# EFM32GG990F1024 register map
File version: 1.6
Registers are 32-bit, read-write, reset 0x0 unless marked. A register's access mark holds for its fields unless they carry their own. Offsets are from the block's base; [hi:lo] are bit positions; {n}, {i} and the like mark numbered series.

## RMU
Base 0x400CA000
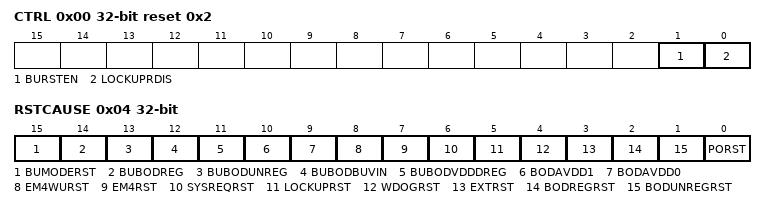
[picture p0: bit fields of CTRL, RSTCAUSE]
0x00 CTRL reset 0x2 — Control Register
  [1] BURSTEN — Backup domain reset enable.
  [0] LOCKUPRDIS — Lockup Reset Disable
0x04 RSTCAUSE ro — Reset Cause Register
  [15] BUMODERST — Backup mode reset
  [14] BUBODREG — Backup Brown Out Detector Regulated Domain
  [13] BUBODUNREG — Backup Brown Out Detector Unregulated Domain
  [12] BUBODBUVIN — Backup Brown Out Detector, BU_VIN
  [11] BUBODVDDDREG — Backup Brown Out Detector, VDD_DREG
  [10] BODAVDD1 — AVDD1 Bod Reset.
  [9] BODAVDD0 — AVDD0 Bod Reset.
  [8] EM4WURST — EM4 Wake-up Reset
  [7] EM4RST — EM4 Reset
  [6] SYSREQRST — System Request Reset
  [5] LOCKUPRST — LOCKUP Reset
  [4] WDOGRST — Watchdog Reset
  [3] EXTRST — External Pin Reset
  [2] BODREGRST — Brown Out Detector Regulated Domain Reset
  [1] BODUNREGRST — Brown Out Detector Unregulated Domain Reset
  [0] PORST — Power On Reset
0x08 CMD wo — Command Register
  [0] RCCLR — Reset Cause Clear

## AES
Base 0x400E0000
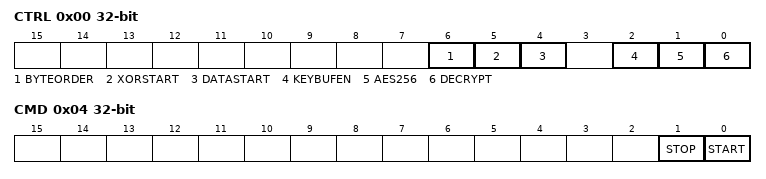
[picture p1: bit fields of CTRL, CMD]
0x00 CTRL — Control Register
  [6] BYTEORDER — Configure byte order in data and key registers
  [5] XORSTART — AES_XORDATA Write Start
  [4] DATASTART — AES_DATA Write Start
  [2] KEYBUFEN — Key Buffer Enable
  [1] AES256 — AES-256 Mode
  [0] DECRYPT — Decryption/Encryption Mode
0x04 CMD wo — Command Register
  [1] STOP — Encryption/Decryption Stop
  [0] START — Encryption/Decryption Start
0x08 STATUS ro
  [0] RUNNING — AES Running
0x0C IEN — Interrupt Enable Register
  [0] DONE — Encryption/Decryption Done Interrupt Enable
0x10 IF ro — Interrupt Flag Register
  [0] DONE — Encryption/Decryption Done Interrupt Flag
0x14 IFS wo — Interrupt Flag Set Register
  [0] DONE — Encryption/Decryption Done Interrupt Flag Set
0x18 IFC wo — Interrupt Flag Clear Register
  [0] DONE — Encryption/Decryption Done Interrupt Flag Clear
0x1C DATA read-has-side-effects
  [31:0] DATA — Data Access
0x20 XORDATA
  [31:0] XORDATA — XOR Data Access
0x30 KEYLA read-has-side-effects — KEY Low Register
  [31:0] KEYLA — Key Low Access A
0x34 KEYLB read-has-side-effects — KEY Low Register
  [31:0] KEYLB — Key Low Access B
0x38 KEYLC read-has-side-effects — KEY Low Register
  [31:0] KEYLC — Key Low Access C
0x3C KEYLD read-has-side-effects — KEY Low Register
  [31:0] KEYLD — Key Low Access D
0x40 KEYHA read-has-side-effects — KEY High Register
  [31:0] KEYHA — Key High Access A
0x44 KEYHB read-has-side-effects — KEY High Register
  [31:0] KEYHB — Key High Access B
0x48 KEYHC read-has-side-effects — KEY High Register
  [31:0] KEYHC — Key High Access C
0x4C KEYHD read-has-side-effects — KEY High Register
  [31:0] KEYHD — Key High Access D

## PRS
Base 0x400CC000
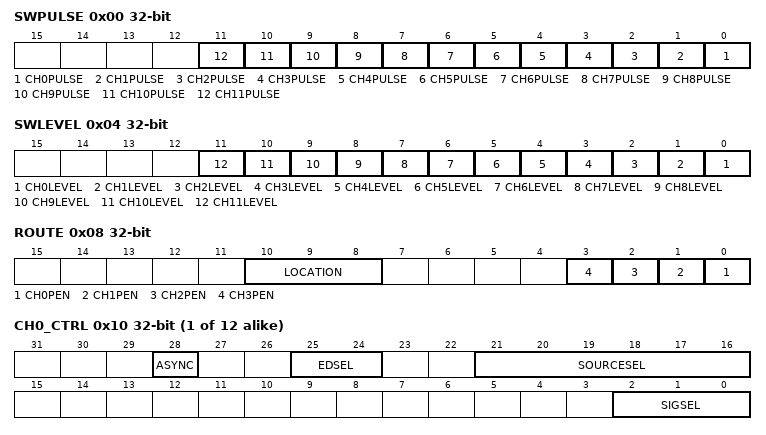
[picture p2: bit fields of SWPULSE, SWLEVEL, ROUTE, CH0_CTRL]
0x00 SWPULSE wo — Software Pulse Register
  [n] CH{n}PULSE (n=0..11) — Channel {n} Pulse Generation
0x04 SWLEVEL — Software Level Register
  [n] CH{n}LEVEL (n=0..11) — Channel {n} Software Level
0x08 ROUTE — I/O Routing Register
  [10:8] LOCATION — I/O Location
    0=LOC0 (Location 0); 1=LOC1 (Location 1)
  [n] CH{n}PEN (n=0..3) — CH{n} Pin Enable
{0x10+4i} CH{i}_CTRL (i=0..11) — Channel Control Register
  [28] ASYNC — Asynchronous reflex
  [25:24] EDSEL — Edge Detect Select
    0=OFF (Signal is left as it is); 1=POSEDGE (A one HFPERCLK cycle pulse is generated for every positive edge of the incoming signal); 2=NEGEDGE (A one HFPERCLK clock cycle pulse is generated for every negative edge of the incoming signal); 3=BOTHEDGES (A one HFPERCLK clock cycle pulse is generated for every edge of the incoming signal)
  [21:16] SOURCESEL — Source Select
    0=NONE (No source selected); 1=VCMP (Voltage Comparator); 2=ACMP0 (Analog Comparator 0); 3=ACMP1 (Analog Comparator 1); 6=DAC0 (Digital to Analog Converter 0); 8=ADC0 (Analog to Digital Converter 0); 16=USART0 (Universal Synchronous/Asynchronous Receiver/Transmitter 0); 17=USART1 (Universal Synchronous/Asynchronous Receiver/Transmitter 1); 18=USART2 (Universal Synchronous/Asynchronous Receiver/Transmitter 2); {v}=TIMER{v-28} (v=28..31); 36=USB (Universal Serial Bus Interface); 40=RTC (Real-Time Counter); 41=UART0 (Universal Asynchronous Receiver/Transmitter 0); 42=UART1 (Universal Asynchronous Receiver/Transmitter 0); 48=GPIOL (General purpose Input/Output); 49=GPIOH (General purpose Input/Output); 52=LETIMER0 (Low Energy Timer 0); 55=BURTC (Backup RTC); 57=LESENSEL (Low Energy Sensor Interface); 58=LESENSEH (Low Energy Sensor Interface); 59=LESENSED (Low Energy Sensor Interface)
  [2:0] SIGSEL — Signal Select
